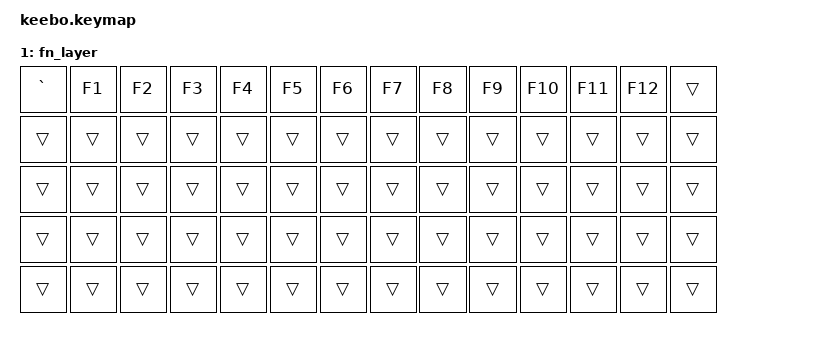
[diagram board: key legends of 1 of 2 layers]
#include <behaviors.dtsi>
#include <dt-bindings/zmk/keys.h>

/ {
    keymap {
        compatible = "zmk,keymap";

        default_layer { // Layer 0
        // ------------------------------------------------------------------------------------------
        // | ESC |  1  |  2  |  3  |  4  |  5  |  6  |  7  |  8  |  9  |  0  |  -  |  =  |   BSPC   |
        // | TAB  |  Q  |  W  |  E  |  R  |  T  |  Y  |  U  |  I  |  O  |  P  |  [  |  ]  |    \    |
        // | CAPS  |  A  |  S  |  D  |  F  |  G  |  H  |  J  |  K  |  L  |  ;  |  '  |     ENTER    |
        // |  SHIFT  |  Z  |  X  |  C  |  V  |  B  |  N  |  M  |  ,  |  .  |  /  |      SHIFT       |
        // |  CTL  |  WIN  |  ALT  |            SPACE               | ALT | MO(1) |  WIN  | CTRL    |
        // ------------------------------------------------------------------------------------------
            bindings = <
                &kp ESC &kp N1 &kp N2 &kp N3 &kp N4 &kp N5 &kp N6 &kp N7 &kp   N8  &kp  N9 &kp  N0  &kp MINUS &kp EQUAL &kp BSPC
                &kp TAB  &kp Q  &kp W  &kp E  &kp R  &kp T  &kp Y  &kp U  &kp   I   &kp  O  &kp   P  &kp LBKT &kp RBKT  &kp BSLH
                &kp CLCK  &kp A  &kp S  &kp D  &kp F  &kp G  &kp H  &kp J  &kp   K   &kp  L  &kp SEMI &kp SQT &kp ENTER &kp UP     
                &kp LSHFT  &kp Z  &kp X  &kp C  &kp V  &kp B  &kp N  &kp M  &kp COMMA &kp PERIOD &kp FSLH &kp RSHFT &kp LEFT &kp DOWN
                &kp LCTRL &kp LWIN &kp LALT               &kp SPACE                 &kp  RALT  &mo 1 &kp K_APP &kp RCTRL &kp RIGHT
            >;

            sensor-bindings = <&inc_dec_kp C_VOL_UP C_VOL_DN>;
        };

        fn_layer {
            bindings = <
                &kp GRAVE &kp F1 &kp F2 &kp F3 &kp F4 &kp F5 &kp F6 &kp F7 &kp F8 &kp F9 &kp F10 &kp F11 &kp F12 &trans
                &trans &trans &trans &trans &trans &trans &trans &trans &trans &trans &trans &trans &trans &trans 
                &trans &trans &trans &trans &trans &trans &trans &trans &trans &trans &trans &trans &trans &trans 
                &trans &trans &trans &trans &trans &trans &trans &trans &trans &trans &trans &trans &trans &trans 
                &trans &trans &trans &trans &trans &trans &trans &trans &trans &trans &trans &trans &trans &trans 
            >;
        };

        sensor-bindings = <&trans>;
        
    };
 };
